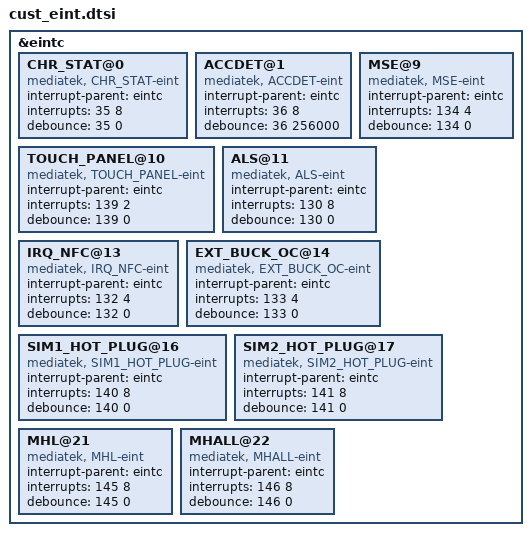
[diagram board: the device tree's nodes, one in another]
/*
 * Generated by MTK SP Drv_CodeGen Version 03.13.6  for MT6752. Copyright MediaTek Inc. (C) 2013.
 * Wed Jun 14 14:18:10 2017
 * Do Not Modify the File.
 */

/*************************
 * EINT DTSI File
*************************/

&eintc {
	CHR_STAT@0 {
		compatible = "mediatek, CHR_STAT-eint";
		interrupt-parent = <&eintc>;
		interrupts = <35 8>;
		debounce = <35 0>;
	};

	ACCDET@1 {
		compatible = "mediatek, ACCDET-eint";
		interrupt-parent = <&eintc>;
		interrupts = <36 8>;
		debounce = <36 256000>;
	};

	MSE@9 {
		compatible = "mediatek, MSE-eint";
		interrupt-parent = <&eintc>;
		interrupts = <134 4>;
		debounce = <134 0>;
	};

	TOUCH_PANEL@10 {
		compatible = "mediatek, TOUCH_PANEL-eint";
		interrupt-parent = <&eintc>;
		interrupts = <139 2>;
		debounce = <139 0>;
	};

	ALS@11 {
		compatible = "mediatek, ALS-eint";
		interrupt-parent = <&eintc>;
		interrupts = <130 8>;
		debounce = <130 0>;
	};

	IRQ_NFC@13 {
		compatible = "mediatek, IRQ_NFC-eint";
		interrupt-parent = <&eintc>;
		interrupts = <132 4>;
		debounce = <132 0>;
	};

	EXT_BUCK_OC@14 {
		compatible = "mediatek, EXT_BUCK_OC-eint";
		interrupt-parent = <&eintc>;
		interrupts = <133 4>;
		debounce = <133 0>;
	};

	SIM1_HOT_PLUG@16 {
		compatible = "mediatek, SIM1_HOT_PLUG-eint";
		interrupt-parent = <&eintc>;
		interrupts = <140 8>;
		debounce = <140 0>;
	};

	SIM2_HOT_PLUG@17 {
		compatible = "mediatek, SIM2_HOT_PLUG-eint";
		interrupt-parent = <&eintc>;
		interrupts = <141 8>;
		debounce = <141 0>;
	};

	MHL@21 {
		compatible = "mediatek, MHL-eint";
		interrupt-parent = <&eintc>;
		interrupts = <145 8>;
		debounce = <145 0>;
	};

	MHALL@22 {
		compatible = "mediatek, MHALL-eint";
		interrupt-parent = <&eintc>;
		interrupts = <146 8>;
		debounce = <146 0>;
	};

};
